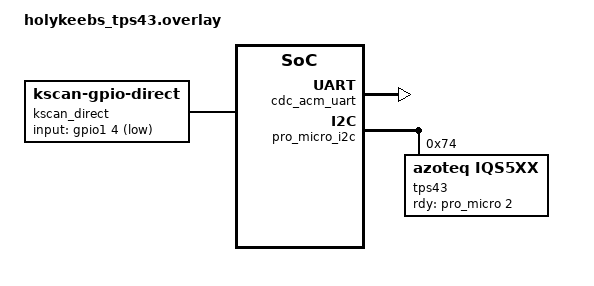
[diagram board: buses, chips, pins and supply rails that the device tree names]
#include <behaviors.dtsi>
#include <dt-bindings/zmk/keys.h>
#include <dt-bindings/zmk/matrix_transform.h>
#include <dt-bindings/zmk/kscan_mock.h>
#include <dt-bindings/i2c/i2c.h>

/ {
	chosen {
		// zmk,kscan = &kscan0;
        zmk,kscan = &kscan_direct;
		zmk,matrix_transform = &tps43_transform;
		zmk,input = &tps43_listener;
		zephyr,console = &cdc_acm_uart;
	};

	tps43_listener: tps43_listener {
		compatible = "zmk,input-listener";
		device = <&tps43>;
	};

	tps43_transform: keymap_transform {
		compatible = "zmk,matrix-transform";
		columns = <1>;
		rows = <1>;
		map = <RC(0, 0)>;
	};

	kscan0: kscan0 {
		compatible = "zmk,kscan-mock";
		rows = <1>;
		columns = <1>;
		events = <ZMK_MOCK_PRESS(0, 0, 100)>;
	};

    kscan_direct: kscan_direct {
        compatible = "zmk,kscan-gpio-direct";
        wakeup-source;

        input-gpios
        = <&gpio1 4 (GPIO_ACTIVE_LOW | GPIO_PULL_UP)>;

    };

	keymap {
		compatible = "zmk,keymap";

		default_layer {
			bindings = <
				&kp ESC
			>;
		};
	};
};

&zephyr_udc0 {
	cdc_acm_uart: cdc_acm_uart {
		compatible = "zephyr,cdc-acm-uart";
		label = "CDC_ACM_0";
		status = "okay";
	};
};

&pro_micro_i2c {
	status = "okay";
	// clock-frequency = <I2C_BITRATE_FAST>;

	tps43: iqs5xx@74 {
		status = "okay";
		compatible = "azoteq,iqs5xx";
		reg = <0x74>;

		rdy-gpios = <&pro_micro 2 GPIO_ACTIVE_HIGH>;
		rotation = <270>;
		flip-y;

		// event-mode;
		one-finger-tap;
		two-finger-tap;
		press-and-hold;
		scroll;
		natural-scroll-x;
		natural-scroll-y;
		// idle-timeout-disable;
		reati;
		report-rate-active = <10>;
		report-rate-idle = <10>;
		report-rate-idle-touch = <10>;
		resolution-x = <2048>;
		resolution-y = <1792>;
	};
};
